AUTOSAR XML (schema 00044)
package /ComponentTypes
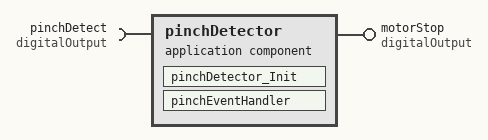
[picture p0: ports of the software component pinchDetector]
  application sw component type pinchDetector
    require port pinchDetect: nonqueued-receiver-com-spec{data-element=outputStatus, filter=data-filter-type=ALWAYS}, required-interface=digitalOutput
    provide port motorStop: nonqueued-sender-com-spec=outputStatus, provided-interface=digitalOutput
    behavior pinchDetector_InternalBehavior
      init event pinchDetector_InitEvent: start-on-event=pinchDetector_Init
      runnable pinchDetector_Init
        data-send-points:
          access SEND_motorStop_outputStatus: accessed-variable=motorStop.outputStatus
      runnable pinchEventHandler
        data-send-points:
          access SEND_motorStop_outputStatus: accessed-variable=motorStop.outputStatus
  swc implementation pinchDetector_Implementation: behavior=pinchDetector_InternalBehavior
